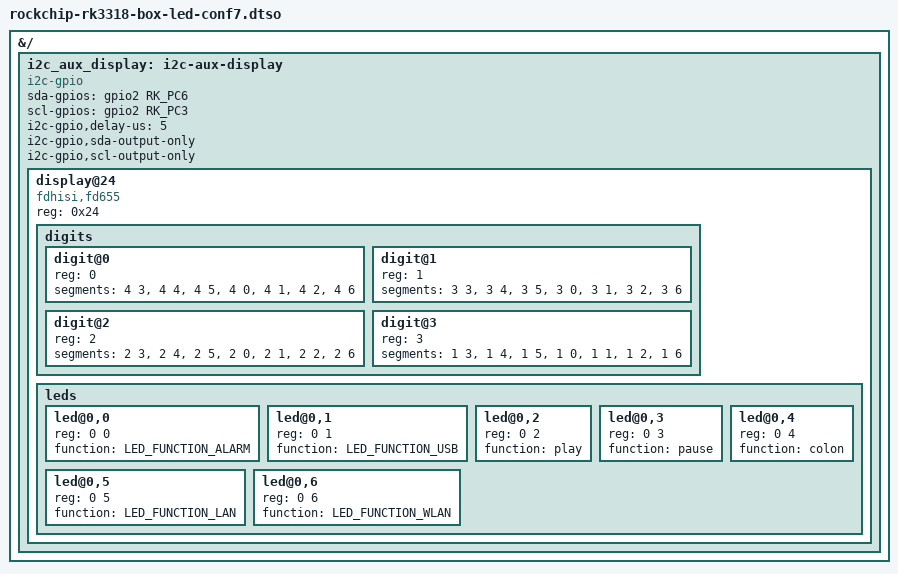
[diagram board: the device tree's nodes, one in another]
/dts-v1/;
/plugin/;

#include <dt-bindings/gpio/gpio.h>
#include <dt-bindings/leds/common.h>
#include <dt-bindings/pinctrl/rockchip.h>

/**
 * T9_RK3318 (T9 Sunwell 3318)
 */

&{/} {

	i2c_aux_display: i2c-aux-display {

		compatible = "i2c-gpio";
		sda-gpios = <&gpio2 RK_PC6 (GPIO_ACTIVE_HIGH|GPIO_OPEN_DRAIN)>;
		scl-gpios = <&gpio2 RK_PC3 (GPIO_ACTIVE_HIGH|GPIO_OPEN_DRAIN)>;
		i2c-gpio,delay-us = <5>;
		i2c-gpio,sda-output-only;
		i2c-gpio,scl-output-only;
		#address-cells = <1>;
		#size-cells = <0>;

		display@24 {
			compatible = "fdhisi,fd655";
			reg = <0x24>;

			digits {
				#address-cells = <1>;
				#size-cells = <0>;

				digit@0 {
					reg = <0>;
					segments = <4 3>, <4 4>, <4 5>, <4 0>, <4 1>, <4 2>, <4 6>;
				};

				digit@1 {
					reg = <1>;
					segments = <3 3>, <3 4>, <3 5>, <3 0>, <3 1>, <3 2>, <3 6>;
				};

				digit@2 {
					reg = <2>;
					segments = <2 3>, <2 4>, <2 5>, <2 0>, <2 1>, <2 2>, <2 6>;
				};

				digit@3{
					reg = <3>;
					segments = <1 3>, <1 4>, <1 5>, <1 0>, <1 1>, <1 2>, <1 6>;
				};

			};

			leds {
				#address-cells = <2>;
				#size-cells = <0>;

				led@0,0 {
					reg = <0 0>;
					function = LED_FUNCTION_ALARM;
				};

				led@0,1 {
					reg = <0 1>;
					function = LED_FUNCTION_USB;
				};

				led@0,2 {
					reg = <0 2>;
					function = "play";
				};

				led@0,3 {
					reg = <0 3>;
					function = "pause";
				};

				led@0,4 {
					reg = <0 4>;
					function = "colon";
				};

				led@0,5 {
					reg = <0 5>;
					function = LED_FUNCTION_LAN;
				};

				led@0,6 {
					reg = <0 6>;
					function = LED_FUNCTION_WLAN;
				};

			};

		};

	};

};
